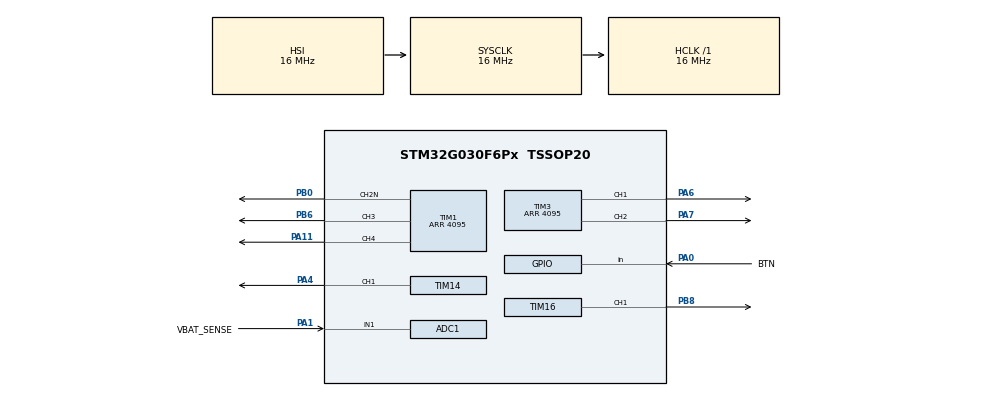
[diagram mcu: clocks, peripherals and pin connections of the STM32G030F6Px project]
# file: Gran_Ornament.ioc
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ADC1.Channel-0\#ChannelRegularConversion=ADC_CHANNEL_1
ADC1.NbrOfConversionFlag=1
ADC1.Rank-0\#ChannelRegularConversion=1
ADC1.SamplingTime-0\#ChannelRegularConversion=ADC_SAMPLINGTIME_COMMON_1
ADC1.SamplingTimeCommon1=ADC_SAMPLETIME_160CYCLES_5
ADC1.SelectedChannel=ADC_CHANNEL_1
ADC1.master=1
Mcu.Family=STM32G0
Mcu.Name=STM32G030F6Px
Mcu.Package=TSSOP20
PA0.GPIO_Label=BTN
PA0.GPIO_PuPd=GPIO_PULLUP
PA0.Signal=GPIO_Input
PA1.GPIO_Label=VBAT_SENSE
PA1.Mode=IN1
PA1.Signal=ADC1_IN1
PA11\ [PA9].GPIO_ModeDefaultPP=GPIO_MODE_AF_OD
PA11\ [PA9].Signal=S_TIM1_CH4
PA13.Mode=Serial_Wire
PA13.Signal=SYS_SWDIO
PA14-BOOT0.Mode=Serial_Wire
PA14-BOOT0.Signal=SYS_SWCLK
PA14-BOOT0__PA15.StandardMode=true
PA4.GPIO_ModeDefaultPP=GPIO_MODE_AF_OD
PA4.Signal=S_TIM14_CH1
PA6.GPIO_ModeDefaultPP=GPIO_MODE_AF_OD
PA6.Signal=S_TIM3_CH1
PA7.GPIO_ModeDefaultPP=GPIO_MODE_AF_OD
PA7.Signal=S_TIM3_CH2
PB0.GPIO_ModeDefaultPP=GPIO_MODE_AF_OD
PB0.Mode=PWM Generation2 CH2N
PB0.Signal=TIM1_CH2N
PB0__PB1__PB2__PA8.StandardMode=true
PB3__PB4__PB5__PB6.StandardMode=true
PB6.GPIO_ModeDefaultPP=GPIO_MODE_AF_OD
PB6.Signal=S_TIM1_CH3
PB7__PB8.StandardMode=true
PB8.GPIO_ModeDefaultPP=GPIO_MODE_AF_OD
PB8.Signal=S_TIM16_CH1
PC14-OSC32_IN\ (PC14)__PB9.StandardMode=true
ProjectManager.HeapSize=0x200
ProjectManager.StackSize=0x400
ProjectManager.TargetToolchain=CMake
RCC.AHBFreq_Value=16000000
RCC.CortexFreq_Value=16000000
RCC.EXTERNAL_CLOCK_VALUE=12288000
RCC.HCLKFreq_Value=16000000
RCC.HSE_VALUE=8000000
RCC.HSI_VALUE=16000000
RCC.LSE_VALUE=32768
RCC.SYSCLKFreq_VALUE=16000000
RCC.VCOOutputFreq_Value=128000000
SH.S_TIM14_CH1.0=TIM14_CH1,PWM Generation1 CH1
SH.S_TIM16_CH1.0=TIM16_CH1,PWM Generation1 CH1
SH.S_TIM1_CH3.0=TIM1_CH3,PWM Generation3 CH3
SH.S_TIM1_CH4.0=TIM1_CH4,PWM Generation4 CH4
SH.S_TIM3_CH1.0=TIM3_CH1,PWM Generation1 CH1
SH.S_TIM3_CH2.0=TIM3_CH2,PWM Generation2 CH2
TIM1.AutoReloadPreload=TIM_AUTORELOAD_PRELOAD_ENABLE
TIM1.Channel-PWM\ Generation2\ CH2N=TIM_CHANNEL_2
TIM1.Channel-PWM\ Generation3\ CH3=TIM_CHANNEL_3
TIM1.Channel-PWM\ Generation4\ CH4=TIM_CHANNEL_4
TIM1.OCNPolarity_2=TIM_OCNPOLARITY_LOW
TIM1.OCPolarity_3=TIM_OCPOLARITY_LOW
TIM1.OCPolarity_4=TIM_OCPOLARITY_LOW
TIM1.Period=4095
TIM14.AutoReloadPreload=TIM_AUTORELOAD_PRELOAD_ENABLE
TIM14.Channel=TIM_CHANNEL_1
TIM14.OCPolarity_1=TIM_OCPOLARITY_LOW
TIM14.Period=4095
TIM16.AutoReloadPreload=TIM_AUTORELOAD_PRELOAD_ENABLE
TIM16.Channel=TIM_CHANNEL_1
TIM16.OCPolarity_1=TIM_OCPOLARITY_LOW
TIM16.Period=4095
TIM3.AutoReloadPreload=TIM_AUTORELOAD_PRELOAD_ENABLE
TIM3.Channel-PWM\ Generation1\ CH1=TIM_CHANNEL_1
TIM3.Channel-PWM\ Generation2\ CH2=TIM_CHANNEL_2
TIM3.OCPolarity_1=TIM_OCPOLARITY_LOW
TIM3.OCPolarity_2=TIM_OCPOLARITY_LOW
TIM3.Period=4095
VP_TIM14_VS_ClockSourceINT.Mode=Enable_Timer
VP_TIM16_VS_ClockSourceINT.Mode=Enable_Timer
VP_TIM3_VS_ClockSourceINT.Mode=Internal
board=custom

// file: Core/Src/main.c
/* USER CODE BEGIN Header */
/**
  ******************************************************************************
  * @file           : main.c
  * @brief          : Main program body
  ******************************************************************************
  * @attention
  *
  * Copyright (c) 2026 STMicroelectronics.
  * All rights reserved.
  *
  * This software is licensed under terms that can be found in the LICENSE file
  * in the root directory of this software component.
  * If no LICENSE file comes with this software, it is provided AS-IS.
  *
  ******************************************************************************
  */
/* USER CODE END Header */
#include "main.h"
#include "adc.h"
#include "tim.h"
#include "gpio.h"

/* USER CODE BEGIN Includes */
#include "app.hpp"
/* USER CODE END Includes */

void SystemClock_Config(void);

int main(void)
{

  /* MCU Configuration--------------------------------------------------------*/

  /* Reset of all peripherals, Initializes the Flash interface and the Systick. */
  HAL_Init();

  /* Configure the system clock */
  SystemClock_Config();

  /* Initialize all configured peripherals */
  MX_GPIO_Init();
  MX_TIM3_Init();
  MX_TIM1_Init();
  MX_TIM14_Init();
  MX_TIM16_Init();
  MX_ADC1_Init();
  /* USER CODE BEGIN 2 */
  app_run();
  /* USER CODE END 2 */

  /* Infinite loop */
  while (1)
  {

  }
}

void SystemClock_Config(void)
{
  RCC_OscInitTypeDef RCC_OscInitStruct = {0};
  RCC_ClkInitTypeDef RCC_ClkInitStruct = {0};

  /** Configure the main internal regulator output voltage
  */
  HAL_PWREx_ControlVoltageScaling(PWR_REGULATOR_VOLTAGE_SCALE1);

  /** Initializes the RCC Oscillators according to the specified parameters
  * in the RCC_OscInitTypeDef structure.
  */
  RCC_OscInitStruct.OscillatorType = RCC_OSCILLATORTYPE_HSI;
  RCC_OscInitStruct.HSIState = RCC_HSI_ON;
  RCC_OscInitStruct.HSIDiv = RCC_HSI_DIV1;
  RCC_OscInitStruct.HSICalibrationValue = RCC_HSICALIBRATION_DEFAULT;
  RCC_OscInitStruct.PLL.PLLState = RCC_PLL_NONE;
  if (HAL_RCC_OscConfig(&RCC_OscInitStruct) != HAL_OK)
  {
    Error_Handler();
  }

  /** Initializes the CPU, AHB and APB buses clocks
  */
  RCC_ClkInitStruct.ClockType = RCC_CLOCKTYPE_HCLK|RCC_CLOCKTYPE_SYSCLK
                              |RCC_CLOCKTYPE_PCLK1;
  RCC_ClkInitStruct.SYSCLKSource = RCC_SYSCLKSOURCE_HSI;
  RCC_ClkInitStruct.AHBCLKDivider = RCC_SYSCLK_DIV1;
  RCC_ClkInitStruct.APB1CLKDivider = RCC_HCLK_DIV1;

  if (HAL_RCC_ClockConfig(&RCC_ClkInitStruct, FLASH_LATENCY_0) != HAL_OK)
  {
    Error_Handler();
  }
}

void Error_Handler(void)
{
  __disable_irq();
  while (1)
  {
  }
}
